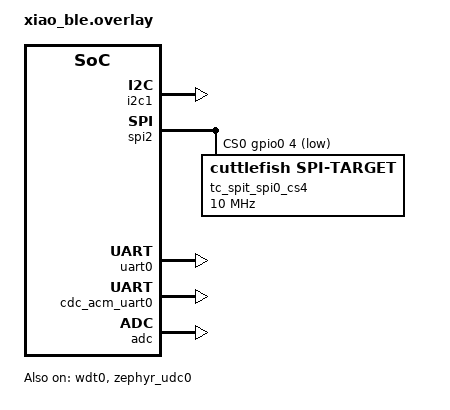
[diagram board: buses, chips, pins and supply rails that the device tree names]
/* Auto-generated by @typecad/framework-zephyr from cuttlefish.config.ts. */
/* Enables peripherals the program uses. West merges this over the board DT. */

&i2c1 {
    status = "okay";
};

&spi2 {
    status = "okay";
};

&spi2 {
    status = "okay";
};

&uart0 {
    status = "okay";
};

&wdt0 {
    status = "okay";
};

&zephyr_udc0 {
    status = "okay";
    cdc_acm_uart0: cdc-acm-uart0 {
        compatible = "zephyr,cdc-acm-uart";
    };
};

&adc {
    status = "okay";
};

&spi2 {
    cs-gpios = <&gpio0 4 GPIO_ACTIVE_LOW>;
    tc_spit_spi0_cs4: spidev@0 {
        compatible = "cuttlefish,spi-target";
        reg = <0>;
        spi-max-frequency = <10000000>;
    };
};
